# cslr_sys_001 register map
Vendor: Texas Instruments
Peripheral module from a debugger description file.
Registers are 32-bit, read-only, reset values left out (the file's numbers can be read two ways) unless marked. A register's access mark holds for its fields unless they carry their own. Offsets are as the file gives them; lines under a group give offsets from that group; [hi:lo] are bit positions; {n}, {i} and the like mark numbered series; 'fields as' and 'values as' point back to an identical list; <NAME> marks a mode.

## SYS — System Module (spec version: 1.00.w.01)
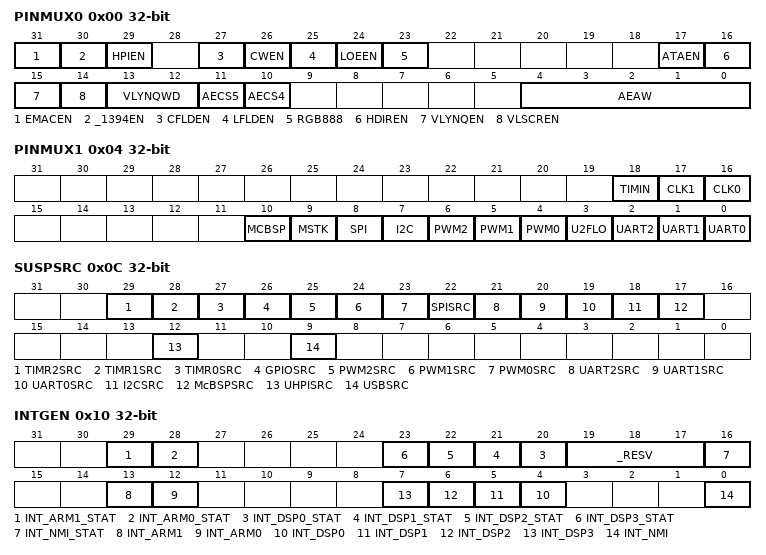
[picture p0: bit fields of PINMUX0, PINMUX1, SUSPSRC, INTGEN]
0x00 PINMUX0 access per field — Pin Mux 0 register - all options
  [31] EMACEN rw — Enable EMAC module pins on GPIO33[0:16]
    0=DISABLE (Disable EMAC pins); 1=ENABLE (Enable EMAC pins)
  [30] _1394EN rw — \hEnable 1394 module pins GPIO33[0:13] . Note that PINMUX0:EMACEN will override this.
    0=DISABLE (Disable 1394 pins); 1=ENABLE (Enable 1394 pins)
  [29] HPIEN rw — \hEnable UHPI module pins on AEMIF bus . Default value MAY be set by BTSEL[1:0] BTSEL[1:0] = 0b10 = 1, otherwise = 0
    0=DISABLE (Disable UHPI signals); 1=ENABLE (Enable UHPI signals)
  [27] CFLDEN rw — Enable CCD C_FIELD pin function on GPIO4/R0
    0=DISABLE; 1=ENABLE
  [26] CWEN rw — Enable CCD _C_WEN function on GPIO3/B0
    0=DISABLE; 1=ENABLE
  [25] LFLDEN rw — Enable LCD_FIELD pin function on GPIO1
    0=DISABLE; 1=ENABLE
  [24] LOEEN rw — Enable LCD_OE pin function on GPIO0
    0=DISABLE; 1=ENABLE
  [23] RGB888 rw — \hEnable VideoOut extended RGB888 mode outputs on GIOs . Note that the following setting will override some pin functions - PINMUX0:CWEN - GPIO3/B0 -> CCD C_WEN signal - PINMUX0:CFLDEN - GPIO4/R0 -> CCD C_FIELD signal - PINMUX1:PWM1 - GIO46/R2 -> PWM1 - PINMUX1:PWM2 - GIO47/B2 -> PWM2
    0=DISABLE; 1=ENABLE
  [17] ATAEN rw — \hEnable ATA module pins . Note that the PINMUX1:UART1 enable will override the ATA signals. DMACK and DMARQ but ATA can still be used in PIO mode. - PINMUX1:UART1 - DMACK -> UART_TXD1 - PINMUX1:UART1 - DMARQ -> UART_RXD1
    0=DISABLE; 1=ENABLE
  [16] HDIREN rw — Enable ATADIR DIR output on GPIO42/SPI_EN1
    0=DISABLE; 1=ENABLE
  [15] VLYNQEN rw — \hEnable VLYNQ module pins . Overrides settngs for: - GPIO[8]/AEMIF_CS[4] - GPIO[9]/AEMIF_CS[5] (if PINMUX0:VLSCREN is enabled) - GPI)[10:17]/EM_A[21:14] (number depends on PINMUX0:VLYNQWD)
    0=DISABLE; 1=ENABLE
  [14] VLSCREN rw — \hEnable VLYNQ SCRUN pin function . Overrides settngs for: - GPIO[9]/AEMIF_CS[5] (if PINMUX0:VLYNQEN is enabled)
    0=DISABLE; 1=ENABLE
  [13:12] VLYNQWD rw — Sets VLYNQ data width
    0=1BIT (1-bit VLYNQ bus (VL_TXD[0]/VL_RXD[0] on EM_A[21:20])); 1=2BIT (2-bit VLYNQ bus (VL_TXD[1:0]/VL_RXD[1:0] on EM_A[21:18])); 2=3BIT (2-bit VLYNQ bus (VL_TXD[2:0]/VL_RXD[2:0] on EM_A[21:16])); 3=4BIT (2-bit VLYNQ bus (VL_TXD[3:0]/VL_RXD[3:0] on EM_A[21:14]))
  [11] AECS5 rw — \hEnable AEMIF ECS5 chip select . Note that the PINMUX0:VLYNQEN enable will override this
    0=DISABLE (Disable AEMIF ECS5); 1=ENABLE (Enable AEMIF ECS5)
  [10] AECS4 rw — \hEnable AEMIF ECS4 chip select . Note that if both PINMUX0:VLYNQEN and PINMUX0:VLSCREN enabled will override this
    0=DISABLE (Disable AEMIF ECS4); 1=ENABLE (Enable AEMIF ECS4)
  [4:0] AEAW rw — \hAEMIF address width selection. See spec table for details. Any seleciton greater than 23 will be interpreted as 23-bits . Note that PINMUX0:VLYNQEN and PINMUX0:VLYNQWD may override some address signals from EM_A[21:14]
    0=0BITS (0-bit AEMIF addr bus selection - _______, EM_A[2:1], GPIO[28:10], GPIO[53:52]); 1=1BIT (1-bit AEMIF addr bus selection - EM_BA[1], EM_A[2:1], GPIO[28:10], GPIO[53]); 2=2BITS (2/4-bit AEMIF addr bus selection - EM_BA[1], EM_A[2:0], GPIO[28:10]); 3=3BITS (3/4-bit AEMIF addr bus selection - EM_BA[1], EM_A[2:0], GPIO[28:10]); 4=4BITS (4-bit AEMIF addr bus selection - EM_BA[1], EM_A[2:0], GPIO[28:10]); 5=5BITS (5-bit AEMIF addr bus selection - EM_BA[1], EM_A[3:0], GPIO[27:10]); 6=6BITS (6-bit AEMIF addr bus selection - EM_BA[1], EM_A[4:0], GPIO[26:10]); 7=7BITS (7-bit AEMIF addr bus selection - EM_BA[1], EM_A[5:0], GPIO[25:10]); 8=8BITS (8-bit AEMIF addr bus selection - EM_BA[1], EM_A[6:0], GPIO[24:10]); 9=9BITS (9-bit AEMIF addr bus selection - EM_BA[1], EM_A[7:0], GPIO[23:10]); 10=10BITS (10-bit AEMIF addr bus selection - EM_BA[1], EM_A[8:0], GPIO[22:10]); 11=11BITS (11-bit AEMIF addr bus selection - EM_BA[1], EM_A[9:0], GPIO[21:10]); 12=12BITS (12-bit AEMIF addr bus selection - EM_BA[1], EM_A[10:0], GPIO[20:10]); 13=13BITS (13-bit AEMIF addr bus selection - EM_BA[1], EM_A[11:0], GPIO[19:10]); 14=14BITS (14-bit AEMIF addr bus selection - EM_BA[1], EM_A[12:0], GPIO[18:10]); 15=15BITS (15-bit AEMIF addr bus selection - EM_BA[1], EM_A[13:0], GPIO[17:10]); 16=16BITS (16-bit AEMIF addr bus selection - EM_BA[1], EM_A[14:0], GPIO[16:10]); 17=17BITS (17-bit AEMIF addr bus selection - EM_BA[1], EM_A[15:0], GPIO[15:10]); 18=18BITS (18-bit AEMIF addr bus selection - EM_BA[1], EM_A[16:0], GPIO[14:10]); 19=19BITS (19-bit AEMIF addr bus selection - EM_BA[1], EM_A[17:0], GPIO[13:10]); 20=20BITS (20-bit AEMIF addr bus selection - EM_BA[1], EM_A[18:0], GPIO[12:10]); 21=21BITS (21-bit AEMIF addr bus selection - EM_BA[1], EM_A[19:0], GPIO[11:10]); 22=22BITS (22-bit AEMIF addr bus selection - EM_BA[1], EM_A[20:0], GPIO[10]); 23=23BITS (23-bit AEMIF addr bus selection - EM_BA[1], EM_A[21:0])
0x04 PINMUX1 access per field
  [all] fields
    0=DISABLE; 1=ENABLE
  [18] TIMIN rw — Enable TIM_IN on GPIO49 / CLKOUT1
  [17] CLK1 rw — Enable CLKOUT1 on GPIO49 Note that the PINMUX1:TIMIN enable will override this
  [16] CLK0 rw — Enable CLKOUT0 on GPIO48
  [10] MCBSP rw — Enable McBSP on GPIO[29:34]
  [9] MSTK rw — Enable Memory Stick on MMC/SD interface
  [8] SPI rw — Enable SPI on GPIO[37:42] Note that PINMUX0:HDIREN will override this
  [7] I2C rw — Enable I2C on GPIO[43:44]
  [6] PWM2 rw — Enable PWM2 on GPIO47
  [5] PWM1 rw — Enable PWM1 on GPIO46/R2
  [4] PWM0 rw — Enable PWM0 on GPIO45/B2
  [3] U2FLO rw — \hEnable UART2 flow control on Upper CCD/Chroma signals . Note that PINMUX1UART2 must also be enabled. UART_CTS2 and#60;- CI[5] / CCD_DATA[13]. UART_RTS2 and#60;- CI[4] / CCD_DATA[12]
  [2] UART2 rw — \hEnable UART2 . UART_RXD2 and#60;- CI[7] / CCD_DATA[15]. UART_TXD2 and#60;- CI[6] / CCD_DATA[14]
  [1] UART1 rw — Enable UART1 on ATA DMACK and DMARQ
  [0] UART0 rw — \hEnable UART0 on GPIO[35:36] . Default value MAY be set by BTSEL[1:0]. BTSEL[1:0] = 0b11 = 1, otherwise = 0
0x08 DSPBOOTADDR rw — DSP Boot Address
  [31:0] DSPBOOTADDR — \hDSP Boot Address . Upper 22 bits of DSP reset vector are stored in upper 22 bits of the register and the 10 LSBs are ignored . Note that this must point to an address range from which GEM can perform instruction fetches. Thus is limited to the following address ranges: L1P : 0x00E0:8000 - 0x00E0:FFFF. AEMIF: 0x42xx:xxxx - 0x4FFF:FFFF (AEMIF shadow region). DDR : 0x8000:0000 - 0x8FFF:FFFF
0x0C SUSPSRC access per field — Determines which processor emulator (ARM or GEM) controls peripheral emulation suspend
  [all] fields
    0=ARMEMU (Receives EMU suspend on ARM suspend); 1=GEMEMU (Receives EMU suspend on GEM suspend)
  [29] TIMR2SRC rw — EMU suspend source for TIMER2 (WDTIMER)
  [28] TIMR1SRC rw — EMU suspend source for TIMER1
  [27] TIMR0SRC rw — EMU suspend source for TIMER0
  [26] GPIOSRC rw — EMU suspend source for GPIO
  [25] PWM2SRC rw — EMU suspend source for PWM2
  [24] PWM1SRC rw — EMU suspend source for PWM1
  [23] PWM0SRC rw — EMU suspend source for PWM0
  [22] SPISRC rw — EMU suspend source for SPI
  [21] UART2SRC rw — EMU suspend source for UART0
  [20] UART1SRC rw — EMU suspend source for UART1
  [19] UART0SRC rw — EMU suspend source for UART0
  [18] I2CSRC rw — EMU suspend source for I2C
  [17] McBSPSRC rw — EMU suspend source for McBSP
  [12] UHPISRC rw — EMU suspend source for UHPI
  [9] USBSRC rw — EMU suspend source for USB
0x10 INTGEN access per field — ARM/DSP Interrupt/Status
  [29] INT_ARM1_STAT rw — ARM1 interrupt signal status
    0=NOINT (no interrupt or has been cleared by writing a '0'); 1=ACTIVEINT (interrupt has occurred and has not been cleared)
  [28] INT_ARM0_STAT rw — ARM0 interrupt signal status
    values as INT_ARM1_STAT
  [n+20] INT_DSP{n}_STAT rw (n=0..3) — DSP{n} interrupt signal status
    values as INT_ARM1_STAT
  [19:17] _RESV ro — DSP3 interrupt signal status
  [16] INT_NMI_STAT rw — NMI (DSP) interrupt signal status
    values as INT_ARM1_STAT
  [13] INT_ARM1 rw — \hARM1 interrupt signal to the ARM. Will always read a 0 except during the cycle when a 1 is written Writing a '1' asserts the interrupt, but bit is cleared to '0' on next cycle
    0=NOINT (No interrupt); 1=SETINT (Set interrupt)
  [12] INT_ARM0 rw — \hARM0 interrupt signal to the ARM. Will always read a 0 except during the cycle when a 1 is written Writing a '1' asserts the interrupt, but bit is cleared to '0' on next cycle
    0=NOINT (No interrupt); 1=SETINT (Set interrupt)
  [n+4] INT_DSP{n} rw (n=0..3) — \hDSP{n} interrupt signal to the DSP. Will always read a 0 except during the cycle when a 1 is written Writing a '1' asserts the interrupt, but bit is cleared to '0' on next cycle
    0=NOINT (No interrupt); 1=SETINT (Set interrupt)
  [0] INT_NMI rw — \hNMI (DSP) interrupt signal to the DSP. Will always read a 0 except during the cycle when a 1 is written Writing a '1' asserts the interrupt, but bit is cleared to '0' on next cycle
    0=NOINT (No interrupt); 1=SETINT (Set interrupt)
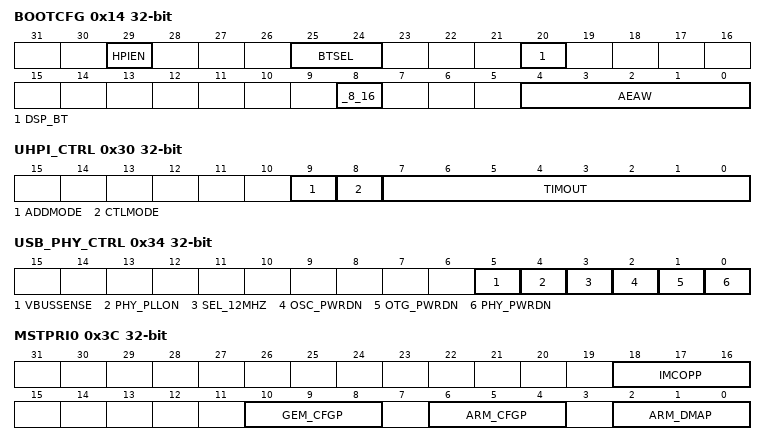
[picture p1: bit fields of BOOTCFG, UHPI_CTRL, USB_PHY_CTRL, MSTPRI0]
0x14 BOOTCFG — Boot Configuration
  [29] HPIEN — \hUHPI module pins selected at boot via BTSEL[1:0]. BTSEL[1:0] = 0b10 = 1, otherwise = 0
    0=DISABLE (No HPI pins); 1=ENABLE (Enable HPI pins)
  [25:24] BTSEL — Configuration at boot of BTSEL[1:0] pins
    0=ROMNAND (Boot from ROM - NAND Flash boot mode); 1=NORFLASH (Boot from AEMIF - NOR Flash); 2=ROMUHPI (Boot from ROM - UHPI boot mode); 3=ROMUART0 (Boot from ROM - UART0 boot mode)
  [20] DSP_BT — Configuraton at boot of DSP_BT pin
    0=ARMBOOT (Disable - ARM boots DSP); 1=DSPBOOT (Enable - DSP boots itself from AEMIF (or ROM if secure))
  [8] _8_16 — Configuratoon at boot of 8_16 pin
    0=_8BITS (8-bit AEMIF CS0 bus); 1=_16BITS (16-bit AEMIF CS0 bus)
  [4:0] AEAW — \hAEMIF address width selection made at boot by AEAW[4:0] pins. See spec table for details . Note that PINMUX0:VLYNQEN and PINMUX0:VLYNQWD may override some address signals from EM_A[21:14]
0x18 VDD1P0V_ADJ — VDD 1.0v Adjust
  [3:0] VDD1P0V_ADJ — Shows VDD 1.0V adjustment programmed in eFuse
0x1C VDD1P2V_ADJ — VDD 1.2v Adjust
  [3:0] VDD1P2V_ADJ — Shows VDD 1.2V adjustment programmed in eFuse
0x20 DDR_SLEW — DDR Slew Rate
  [1:0] DDR_SLEW — Shows DDR I/O cell timing control programmed in eFuse
0x24 MV_ENABLE — Macrovision Enable
  [0] MV_ENABLE — Macrovision module enable as programmed in eFuse
    0=DISABLE (Macrovision disabled); 1=ENABLE (Macrovision enabled)
0x28 OHCI1394EN — OHCI1394 Enable
  [0] _1394EN — OHCI1394 module enable as programmed in eFuse
    0=DISABLE (OHCI1394 disabled); 1=ENABLE (OHCI1394 enabled)
0x2C DAC_DEMEN — DAC DEMEN Status
  [0] DAC_DMEN — State of DEMEN programmed in eFuse
    0=DISABLE (DAC Dynamic Element Matching disabled); 1=ENABLE (DAC Dynamic Element Matching enabled)
0x30 UHPI_CTRL access per field — UHPI Control
  [9] ADDMODE rw — Determines write access of HPIA Register
    0=HOSTWRITE (Host write access); 1=CPUWRITE (CPU write access)
  [8] CTLMODE rw — Determines write access of HPIC Register
    values as ADDMODE
  [7:0] TIMOUT rw — Burst write timeout value
0x34 USB_PHY_CTRL access per field — USB PHY Control
  [5] VBUSSENSE ro — Captures output of OTG analog block
  [4] PHY_PLLON rw — USB PHY PLL state
    0=NORMAL (Normal operation); 1=Override PLL suspend state
  [3] SEL_12MHZ rw — Select 12MHz to CLK_OUT1
    0=24MHZ (24MHz output to CLK_OUT1); 1=12MHZ (12MHz output to CLK_OUT1)
  [2] OSC_PWRDN rw — USB PHY Oscillator Powerdown
    0=NORMAL; 1=PWRDN (Powerdown)
  [1] OTG_PWRDN rw — USB PHY OTG Analog Block Powerdown
    0=NORMAL; 1=PWRDN (Powerdown)
  [0] PHY_PWRDN rw — USB PHY Powerdown
    0=NORMAL; 1=PWRDN (Powerdown)
0x38 CHIP_SHORT_SWITCH access per field — Chip Shorting Switch for DSP
  [0] DSPPWRON rw — Controls power supply shorting switch for DSP Default state set by DSP_BT value
    0=OFF (Shorting switch open); 1=ON (Shorting Switch Closed)
0x3C MSTPRI0 access per field — Master Priorities Reg0
  [18:16] IMCOPP rw — Image Coprocessor bus priority
  [10:8] GEM_CFGP rw — GEM CFG bus priority
  [6:4] ARM_CFGP rw — ARM CFG bus priority
  [2:0] ARM_DMAP rw — ARM DMA priority
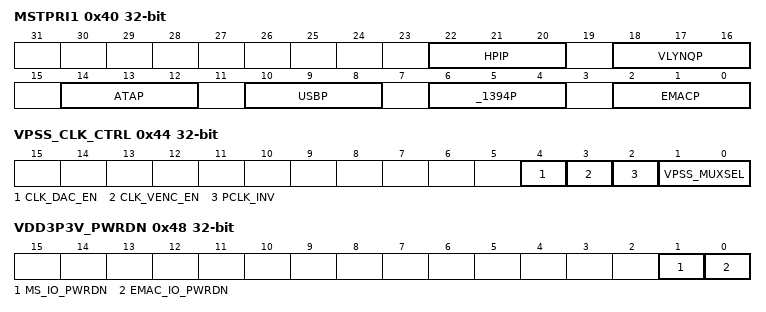
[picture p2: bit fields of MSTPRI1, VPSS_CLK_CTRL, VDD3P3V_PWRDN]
0x40 MSTPRI1 access per field — Master Priorities Reg1
  [22:20] HPIP rw — UHPI bus priority
  [18:16] VLYNQP rw — VLYNQ bus priority
  [14:12] ATAP rw — ATA bus priority
  [10:8] USBP rw — USB bus priority
  [6:4] _1394P rw — 1394 bus priority
  [2:0] EMACP rw — EMAC bus priority
0x44 VPSS_CLK_CTRL access per field — VPSS Clock Mux Control
  [4] CLK_DAC_EN rw — Enable Video DAC clock
    0=DISABLE; 1=ENABLE
  [3] CLK_VENC_EN rw — Enable VPBE/Video Encoder clock
    0=DISABLE; 1=ENABLE
  [2] PCLK_INV rw — Invert VPFE pixel clock (PCLK)
    0=DISABLE (Use normal PCLK); 1=ENABLE (Use inverted PCLK)
  [1:0] VPSS_MUXSEL rw — VPSS clock selection
    0=27MHZ (Use 27MHX (from MXI27)); 1=54MHZ (Use 54MHX (from PLLCTRL2)); 2=VPBECLK (Use VPBE input clock (VPBECLK)); 3=PCLK (Use VPFE input clock (PCLK))
0x48 VDD3P3V_PWRDN access per field — VDD 3.3v Powerdwn
  [1] MS_IO_PWRDN rw — Powerdown MMC/SD/MS output cells
    0=NORMAL; 1=PWRDN (Powerdown)
  [0] EMAC_IO_PWRDN rw — Powerdown EMAC/1394 output cells
    0=NORMAL; 1=PWRDN (Powerdown)
0x50 SEC_SCAN_REG — Secure Scan Register
  [2:0] TBD1 — Need info
0x54 SEC_TEST_REG — Secure Test Register
  [2:0] TBD1 — Need info
0x58 SEC_TAP_CTL — Secure TAP Control
  [2:0] TBD1 — Need info
{0x5C+4i} PUBLIC_KEY{i} (i=0..3) — Public Key Register {i}
  [31:0] PUBLIC_KEY{i} — Bits [{32i+31}:{32i}] of the public key
